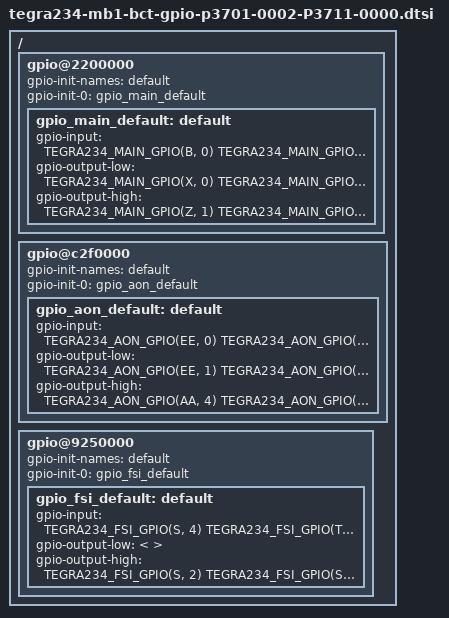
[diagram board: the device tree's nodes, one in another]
/*This dtsi file was generated by p3710_sku0_mandalore_a01.xlsm Revision: 107 */
/*
 * Copyright (c) 2021-2022, NVIDIA CORPORATION.  All rights reserved.
 *
 * This program is free software; you can redistribute it and/or modify
 * it under the terms of the GNU General Public License as published by
 * the Free Software Foundation; either version 2 of the License, or
 * (at your option) any later version.
 *
 * This program is distributed in the hope that it will be useful, but WITHOUT
 * ANY WARRANTY; without even the implied warranty of MERCHANTABILITY or
 * FITNESS FOR A PARTICULAR PURPOSE.  See the GNU General Public License for
 * more details.
 */

#include "tegra234-gpio.h"


/ {
	gpio@2200000 {
		gpio-init-names = "default";
		gpio-init-0 = <&gpio_main_default>;

		gpio_main_default: default {
			gpio-input = <
				TEGRA234_MAIN_GPIO(B, 0)
				TEGRA234_MAIN_GPIO(Y, 5)
				TEGRA234_MAIN_GPIO(Z, 7)
				TEGRA234_MAIN_GPIO(P, 1)
				TEGRA234_MAIN_GPIO(P, 4)
				TEGRA234_MAIN_GPIO(Q, 1)
				TEGRA234_MAIN_GPIO(Q, 4)
				TEGRA234_MAIN_GPIO(R, 4)
				TEGRA234_MAIN_GPIO(G, 0)
				TEGRA234_MAIN_GPIO(G, 1)
				TEGRA234_MAIN_GPIO(G, 4)
				TEGRA234_MAIN_GPIO(G, 7)
				TEGRA234_MAIN_GPIO(J, 0)
				TEGRA234_MAIN_GPIO(J, 1)
				TEGRA234_MAIN_GPIO(J, 2)
				TEGRA234_MAIN_GPIO(J, 4)
				TEGRA234_MAIN_GPIO(AC, 0)
				TEGRA234_MAIN_GPIO(AC, 2)
				TEGRA234_MAIN_GPIO(AC, 3)
				TEGRA234_MAIN_GPIO(AC, 5)
				TEGRA234_MAIN_GPIO(K, 6)
				TEGRA234_MAIN_GPIO(K, 7)
				TEGRA234_MAIN_GPIO(L, 2)
				TEGRA234_MAIN_GPIO(AG, 2)
				TEGRA234_MAIN_GPIO(AG, 3)
				TEGRA234_MAIN_GPIO(AG, 6)
				TEGRA234_MAIN_GPIO(AG, 7)
				TEGRA234_MAIN_GPIO(A, 1)
				TEGRA234_MAIN_GPIO(A, 2)
				TEGRA234_MAIN_GPIO(A, 3)
				TEGRA234_MAIN_GPIO(AF, 3)
				>;
			gpio-output-low = <
				TEGRA234_MAIN_GPIO(X, 0)
				TEGRA234_MAIN_GPIO(X, 1)
				TEGRA234_MAIN_GPIO(P, 6)
				TEGRA234_MAIN_GPIO(Q, 3)
				TEGRA234_MAIN_GPIO(R, 1)
				TEGRA234_MAIN_GPIO(I, 5)
				TEGRA234_MAIN_GPIO(K, 0)
				TEGRA234_MAIN_GPIO(L, 3)
				>;
			gpio-output-high = <
				TEGRA234_MAIN_GPIO(Z, 1)
				TEGRA234_MAIN_GPIO(R, 5)
				TEGRA234_MAIN_GPIO(G, 3)
				TEGRA234_MAIN_GPIO(G, 5)
				TEGRA234_MAIN_GPIO(K, 4)
				TEGRA234_MAIN_GPIO(K, 5)
				TEGRA234_MAIN_GPIO(AG, 4)
				TEGRA234_MAIN_GPIO(AG, 5)
				>;
		};
	};
	gpio@c2f0000 {
		gpio-init-names = "default";
		gpio-init-0 = <&gpio_aon_default>;

		gpio_aon_default: default {
			gpio-input = <
				TEGRA234_AON_GPIO(EE, 0)
				TEGRA234_AON_GPIO(EE, 6)
				TEGRA234_AON_GPIO(EE, 3)
				TEGRA234_AON_GPIO(EE, 4)
				>;
			gpio-output-low = <
				TEGRA234_AON_GPIO(EE, 1)
				TEGRA234_AON_GPIO(EE, 5)
				>;
			gpio-output-high = <
				TEGRA234_AON_GPIO(AA, 4)
				TEGRA234_AON_GPIO(BB, 0)
				TEGRA234_AON_GPIO(BB, 1)
				>;
		};
	};
	gpio@9250000 {
		gpio-init-names = "default";
		gpio-init-0 = <&gpio_fsi_default>;

		gpio_fsi_default: default {
			gpio-input = <
				TEGRA234_FSI_GPIO(S, 4)
				TEGRA234_FSI_GPIO(T, 1)
				TEGRA234_FSI_GPIO(W, 0)
				TEGRA234_FSI_GPIO(W, 1)
				>;
			gpio-output-low = <
				>;
			gpio-output-high = <
				TEGRA234_FSI_GPIO(S, 2)
				TEGRA234_FSI_GPIO(S, 7)
				>;
		};
	};

};
